# CORE_PRM register map
Vendor: Texas Instruments
Peripheral module from a debugger description file (folder omap5430_ES2_PUBLIC).
Registers are 32-bit, access not given, reset 0x1 unless marked. A register's access mark holds for its fields unless they carry their own. Offsets are as the file gives them; lines under a group give offsets from that group; [hi:lo] are bit positions; {n}, {i} and the like mark numbered series; 'fields as' and 'values as' point back to an identical list; <NAME> marks a mode.

## CORE_PRM
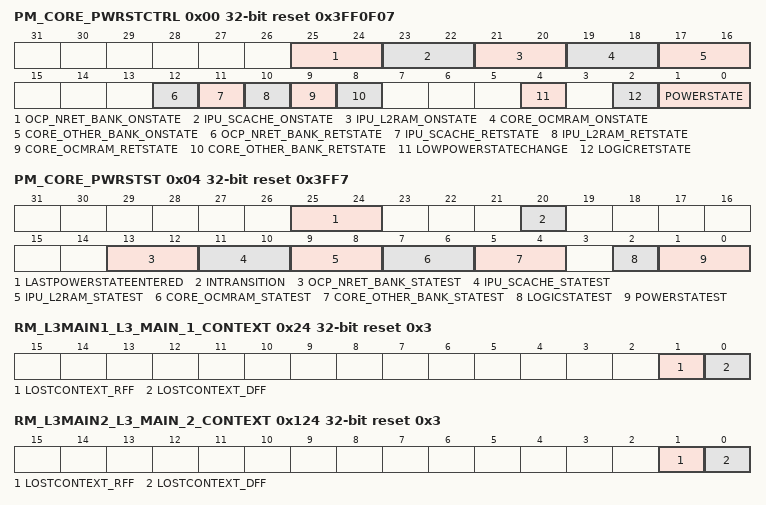
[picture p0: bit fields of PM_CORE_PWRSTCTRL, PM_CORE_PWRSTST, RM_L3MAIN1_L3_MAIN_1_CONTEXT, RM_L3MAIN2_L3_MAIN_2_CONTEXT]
0x00 PM_CORE_PWRSTCTRL reset 0x3FF0F07 — This register controls the CORE power state to reach upon a domain sleep transition
  [25:24] OCP_NRET_BANK_ONSTATE ro — OCP_NRET_BANK state when domain is ON.
    3=Mem_on (Memory bank is on when the domain is ON.)
  [23:22] IPU_SCACHE_ONSTATE ro — IPU SCACHE bank state when domain is ON.
    3=ON._3 (Memory bank is on when the domain is ON.)
  [21:20] IPU_L2RAM_ONSTATE ro — IPU L2 bank state when domain is ON.
    3=Mem_on (Memory bank is on when the domain is ON.)
  [19:18] CORE_OCMRAM_ONSTATE ro — OCMRAM bank state when domain is ON.
    3=Mem_on (Memory bank is on when the domain is ON.)
  [17:16] CORE_OTHER_BANK_ONSTATE ro — CORE_OTHER_BANK state when domain is ON.
    3=Mem_on (Memory bank is on when the domain is ON.)
  [12] OCP_NRET_BANK_RETSTATE ro — OCP_NRET_BANK state when domain is RETENTION.
    0=mem_off (Memory bank is off when the domain is in the RETENTION state.)
  [11] IPU_SCACHE_RETSTATE rw — IPU SCACHE bank state when domain is RETENTION.
    0=RETENTION_0 (Memory bank is off when the domain is in the RETENTION state.); 1=RETENTION_1 (Memory bank is retained when domain is in RETENTION state.)
  [10] IPU_L2RAM_RETSTATE rw — IPU L2 bank state when domain is RETENTION.
    0=mem_off (Memory bank is off when the domain is in the RETENTION state.); 1=mem_ret (Memory bank is retained when domain is in RETENTION state.)
  [9] CORE_OCMRAM_RETSTATE ro — OCMRAM bank state when domain is RETENTION.
    1=mem_ret (Memory bank is retained when domain is in RETENTION state.)
  [8] CORE_OTHER_BANK_RETSTATE ro — CORE_OTHER_BANK state when domain is RETENTION.
    values as CORE_OCMRAM_RETSTATE
  [4] LOWPOWERSTATECHANGE — Power state change request when domain has already performed a sleep transition. Allows going into deeper low power state without waking up the power domain. (access RW WSpecial)
    0=DIS (Do not request a low power state change.); 1=EN (Request a low power state change. This bit is automatically cleared when the power state is effectively changed or when power state is ON.)
  [2] LOGICRETSTATE rw — Logic state when power domain is RETENTION
    0=logic_off (Only retention registers are retained and remaing logic is off when the domain is in RETENTION state.); 1=logic_ret (Whole logic is retained when domain is in RETENTION state.)
  [1:0] POWERSTATE rw — Power state control
    1=RET (RETENTION state); 2=INACT (INACTIVE state); 3=ON (ON State)
0x04 PM_CORE_PWRSTST reset 0x3FF7 — This register provides a status on the current CORE power domain state. [warm reset insensitive]
  [25:24] LASTPOWERSTATEENTERED — Last low power state entered. Set to 0x3 upon write of the same only. This register is intended for debug purpose only. (access RW W1toSet)
    3=ON (Power domain was previously ON-ACTIVE); 2=INACTIVE (Power domain was previously ON-INACTIVE); 1=RET (Power domain was previously in RETENTION); 0=OFF (Reserved)
  [20] INTRANSITION ro — Domain transition status
    0=No (No on-going transition on power domain); 1=Ongoing (Power domain transition is in progress.)
  [13:12] OCP_NRET_BANK_STATEST ro — OCP_NRET_BANK bank state status
    0=Mem_off (Reserved); 3=Mem_on (Memory is ON)
  [11:10] IPU_SCACHE_STATEST ro — IPU SCACHE bank state status
    1=Memory_is_RETENTION; 3=Memory_is_ON
  [9:8] IPU_L2RAM_STATEST ro — IPU L2 bank state status
    0=Mem_off (Reserved); 1=Mem_ret (Memory is RETENTION); 3=Mem_on (Memory is ON)
  [7:6] CORE_OCMRAM_STATEST ro — OCMRAM bank state status
    values as IPU_L2RAM_STATEST
  [5:4] CORE_OTHER_BANK_STATEST ro — CORE_OTHER_BANK state status
    values as IPU_L2RAM_STATEST
  [2] LOGICSTATEST ro — Logic state status
    0=OFF (Logic in domain is OFF); 1=ON (Logic in domain is ON)
  [1:0] POWERSTATEST ro — Current power state status
    1=RET (Power domain is in RETENTION); 2=INACTIVE (Power domain is ON-INACTIVE); 3=ON (Power domain is ON-ACTIVE)
0x24 RM_L3MAIN1_L3_MAIN_1_CONTEXT reset 0x3 — This register contains dedicated L3_MAIN1 context statuses. [warm reset insensitive]
  [1] LOSTCONTEXT_RFF — Specify if RFF-based context has been lost due to a previous power transition or other reset source. (set upon assertion of CORE_PWRON_RET_RST signal) (access RW W1toClr)
    0=Maintained (Context has been maintained); 1=Lost (Context has been lost)
  [0] LOSTCONTEXT_DFF — Specify if DFF-based context has been lost due to a previous power transition or other reset source. (set upon assertion of CORE_RST signal) (access RW W1toClr)
    values as LOSTCONTEXT_RFF
0x124 RM_L3MAIN2_L3_MAIN_2_CONTEXT reset 0x3 — This register contains dedicated L3_MAIN2 context statuses. [warm reset insensitive]
  fields as RM_L3MAIN1_L3_MAIN_1_CONTEXT
0x12C RM_L3MAIN2_GPMC_CONTEXT reset 0x2 — This register contains dedicated GPMC context statuses. [warm reset insensitive]
  [1] LOSTCONTEXT_RFF — Specify if RFF-based context has been lost due to a previous power transition or other reset source. (set upon assertion of CORE_RET_RST signal) (access RW W1toClr)
    values as RM_L3MAIN1_L3_MAIN_1_CONTEXT.LOSTCONTEXT_RFF
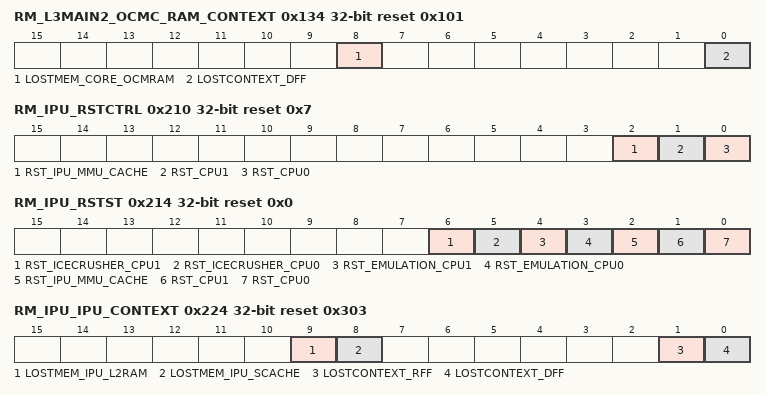
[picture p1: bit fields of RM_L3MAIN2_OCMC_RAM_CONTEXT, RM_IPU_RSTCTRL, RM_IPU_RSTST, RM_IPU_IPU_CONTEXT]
0x134 RM_L3MAIN2_OCMC_RAM_CONTEXT reset 0x101 — This register contains dedicated OCMC_RAM context statuses. [warm reset insensitive]
  [8] LOSTMEM_CORE_OCMRAM — Specify if memory-based context in CORE_OCMRAM memory bank has been lost due to a previous power transition or other reset source (not affected by a global warm reset). (access RW W1toClr)
    values as RM_L3MAIN1_L3_MAIN_1_CONTEXT.LOSTCONTEXT_RFF
  [0] LOSTCONTEXT_DFF — Specify if DFF-based context has been lost due to a previous power transition or other reset source. (set upon assertion of CORE_RST signal) (access RW W1toClr)
    values as RM_L3MAIN1_L3_MAIN_1_CONTEXT.LOSTCONTEXT_RFF
0x210 RM_IPU_RSTCTRL access per field reset 0x7 — This register controls the release of the IPU sub-system resets.
  [2] RST_IPU_MMU_CACHE rw — IPU MMU and CACHE interface reset control.
    0=CLEAR (Reset is cleared for IPU CACHE and MMU); 1=ASSERT (Reset is asserted for the IPU CACHE and MMU)
  [1] RST_CPU1 rw — IPU CPU1 reset control.
    0=CLEAR (Reset is cleared for the IPU CPU1); 1=ASSERT (Reset is asserted for the IPU CPU1)
  [0] RST_CPU0 rw — IPU CPU0 reset control.
    0=CLEAR (Reset is cleared for the IPU CPU0); 1=ASSERT (Reset is asserted for the IPU CPU0)
0x214 RM_IPU_RSTST reset 0x0 — This register logs the different reset sources of the IPU SS. Each bit is set upon release of the domain reset signal. Must be cleared by software. [warm reset insensitive]
  [6] RST_ICECRUSHER_CPU1 — IPU CPU1 has been reset due to IPU ICECRUSHER1 reset source (access RW W1toClr)
    0=RESET_NO (No icecrusher reset); 1=RESET_YES (IPU CPU1 has been reset upon icecrusher reset)
  [5] RST_ICECRUSHER_CPU0 — IPU CPU0 has been reset due to IPU ICECRUSHER0 reset source (access RW W1toClr)
    0=RESET_NO (No icecrusher reset); 1=RESET_YES (CPU0 has been reset upon icecrusher reset)
  [4] RST_EMULATION_CPU1 — IPU CPU1 has been reset due to emulation reset source e.g. assert reset command initiated by the icepick module (access RW W1toClr)
    0=RESET_NO (No emulation reset); 1=RESET_YES (IPU CPU1 has been reset upon emulation reset)
  [3] RST_EMULATION_CPU0 — IPU CPU0 has been reset due to emulation reset source e.g. assert reset command initiated by the icepick module (access RW W1toClr)
    0=RESET_NO (No emulation reset); 1=RESET_YES (IPU CPU0 has been reset upon emulation reset)
  [2] RST_IPU_MMU_CACHE — IPU MMU and CACHE interface SW reset status (access RW W1toClr)
    0=RESET_NO (No SW reset occured); 1=RESET_YES (IPU MMU and CACHE interface has been reset upon SW reset)
  [1] RST_CPU1 — IPU CPU1 SW reset status (access RW W1toClr)
    0=RESET_NO (No SW reset occured); 1=RESET_YES (IPU CPU1 has been reset upon SW reset)
  [0] RST_CPU0 — IPU CPU0 SW reset status (access RW W1toClr)
    0=RESET_NO (No SW reset occured); 1=RESET_YES (IPU CPU0 has been reset upon SW reset)
0x224 RM_IPU_IPU_CONTEXT reset 0x303 — This register contains dedicated IPU context statuses. [warm reset insensitive]
  [9] LOSTMEM_IPU_L2RAM — Specify if memory-based context in IPU_L2RAM memory bank has been lost due to a previous power transition or other reset source. (access RW W1toClr)
    values as RM_L3MAIN1_L3_MAIN_1_CONTEXT.LOSTCONTEXT_RFF
  [8] LOSTMEM_IPU_SCACHE — Specify if memory-based context in IPU_SCACHE memory bank has been lost due to a previous power transition or other reset source. (access RW W1toClr)
    0=Context_has_been_maintained; 1=Context_has_been_lost
  [1] LOSTCONTEXT_RFF — Specify if RFF-based context has been lost due to a previous power transition or other reset source. (set upon assertion of IPU_RET_RST signal) (access RW W1toClr)
    values as RM_L3MAIN1_L3_MAIN_1_CONTEXT.LOSTCONTEXT_RFF
  [0] LOSTCONTEXT_DFF — Specify if DFF-based context has been lost due to a previous power transition or other reset source. (set upon assertion of IPU_RST3 signal) (access RW W1toClr)
    values as RM_L3MAIN1_L3_MAIN_1_CONTEXT.LOSTCONTEXT_RFF
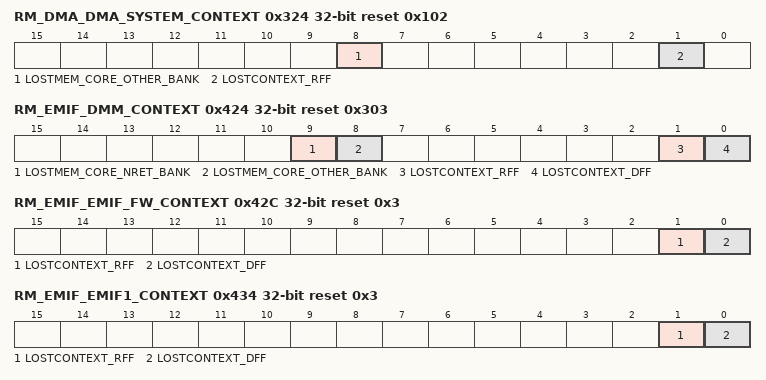
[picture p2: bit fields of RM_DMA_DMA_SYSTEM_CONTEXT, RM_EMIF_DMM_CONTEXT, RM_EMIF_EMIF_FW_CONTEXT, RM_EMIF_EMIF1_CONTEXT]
0x324 RM_DMA_DMA_SYSTEM_CONTEXT reset 0x102 — This register contains dedicated DMA_SYSTEM context statuses. [warm reset insensitive]
  [8] LOSTMEM_CORE_OTHER_BANK — Specify if memory-based context in CORE_OTHER_BANK memory bank has been lost due to a previous power transition or other reset source. (access RW W1toClr)
    values as RM_L3MAIN1_L3_MAIN_1_CONTEXT.LOSTCONTEXT_RFF
  [1] LOSTCONTEXT_RFF — Specify if RFF-based context has been lost due to a previous power transition or other reset source. (set upon assertion of SDMA_RET_RST signal) (access RW W1toClr)
    values as RM_L3MAIN1_L3_MAIN_1_CONTEXT.LOSTCONTEXT_RFF
0x424 RM_EMIF_DMM_CONTEXT reset 0x303 — This register contains dedicated DMM context statuses. [warm reset insensitive]
  [all] fields
    values as RM_L3MAIN1_L3_MAIN_1_CONTEXT.LOSTCONTEXT_RFF
  [9] LOSTMEM_CORE_NRET_BANK — Specify if memory-based context in CORE_NRET_BANK memory bank has been lost due to a previous power transition or other reset source. (access RW W1toClr)
  [8] LOSTMEM_CORE_OTHER_BANK — Specify if memory-based context in CORE_OTHER_BANK memory bank has been lost due to a previous power transition or other reset source. (access RW W1toClr)
  [1] LOSTCONTEXT_RFF — Specify if RFF-based context has been lost due to a previous power transition or other reset source. (set upon assertion of CORE_RET_RST signal) (access RW W1toClr)
  [0] LOSTCONTEXT_DFF — Specify if DFF-based context has been lost due to a previous power transition or other reset source. (set upon assertion of CORE_RST signal) (access RW W1toClr)
0x42C RM_EMIF_EMIF_FW_CONTEXT reset 0x3 — This register contains dedicated EMIF_FW context statuses. [warm reset insensitive]
  [1] LOSTCONTEXT_RFF — Specify if RFF-based context has been lost due to a previous power transition or other reset source. (set upon assertion of CORE_PWRON_RET_RST signal) (access RW W1toClr)
    0=Context_has_been_maintained; 1=Context_has_been_lost
  [0] LOSTCONTEXT_DFF — Specify if DFF-based context has been lost due to a previous power transition or other reset source. (set upon assertion of CORE_RST signal) (access RW W1toClr)
    0=Context_has_been_maintained; 1=Context_has_been_lost
0x434 RM_EMIF_EMIF1_CONTEXT reset 0x3 — This register contains dedicated EMIF1 context statuses. [warm reset insensitive]
  [1] LOSTCONTEXT_RFF — Specify if RFF-based context has been lost due to a previous power transition or other reset source. (set upon assertion of CORE_PWRON_RET_RST signal) (access RW W1toClr)
    values as RM_L3MAIN1_L3_MAIN_1_CONTEXT.LOSTCONTEXT_RFF
  [0] LOSTCONTEXT_DFF — Specify if DFF-based context has been lost due to a previous power transition or other reset source. (set upon assertion of CORE_PWRON_RST signal) (access RW W1toClr)
    values as RM_L3MAIN1_L3_MAIN_1_CONTEXT.LOSTCONTEXT_RFF
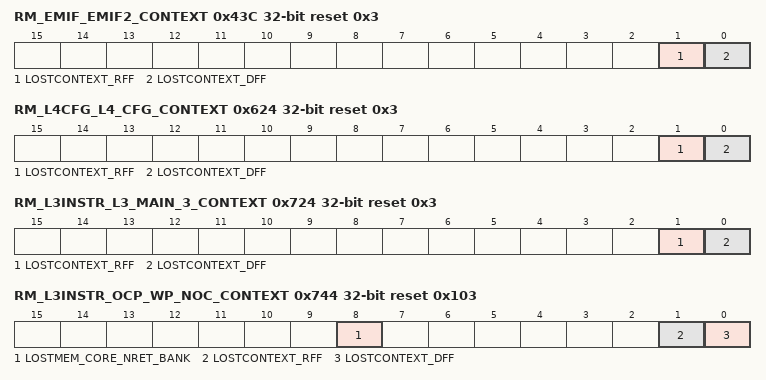
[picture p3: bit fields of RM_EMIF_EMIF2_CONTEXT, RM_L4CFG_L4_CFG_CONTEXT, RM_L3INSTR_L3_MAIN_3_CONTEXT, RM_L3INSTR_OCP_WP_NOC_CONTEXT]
0x43C RM_EMIF_EMIF2_CONTEXT reset 0x3 — This register contains dedicated EMIF2 context statuses. [warm reset insensitive]
  fields as RM_EMIF_EMIF1_CONTEXT
0x444 RM_EMIF_EMIF_DLL_CONTEXT — This register contains dedicated DLL context statuses. [warm reset insensitive]
  [0] LOSTCONTEXT_DFF — Specify if DFF-based context has been lost due to a previous power transition or other reset source. (set upon assertion of DLL_RST signal) (access RW W1toClr)
    values as RM_L3MAIN1_L3_MAIN_1_CONTEXT.LOSTCONTEXT_RFF
0x624 RM_L4CFG_L4_CFG_CONTEXT reset 0x3 — This register contains dedicated L4_CFG context statuses. [warm reset insensitive]
  fields as RM_L3MAIN1_L3_MAIN_1_CONTEXT
0x62C RM_L4CFG_SPINLOCK_CONTEXT reset 0x2 — This register contains dedicated HW_SEM context statuses. [warm reset insensitive]
  fields as RM_L3MAIN2_GPMC_CONTEXT
0x634 RM_L4CFG_MAILBOX_CONTEXT reset 0x2 — This register contains dedicated MAILBOX context statuses. [warm reset insensitive]
  fields as RM_L3MAIN2_GPMC_CONTEXT
0x63C RM_L4CFG_SAR_ROM_CONTEXT — This register contains dedicated SAR_ROM context statuses. [warm reset insensitive]
  [0] LOSTCONTEXT_DFF — Specify if DFF-based context has been lost due to a previous power transition or other reset source. (set upon assertion of CORE_RST signal) (access RW W1toClr)
    values as RM_L3MAIN1_L3_MAIN_1_CONTEXT.LOSTCONTEXT_RFF
0x724 RM_L3INSTR_L3_MAIN_3_CONTEXT reset 0x3 — This register contains dedicated L3_MAIN3 context statuses. [warm reset insensitive]
  fields as RM_L3MAIN1_L3_MAIN_1_CONTEXT
0x72C RM_L3INSTR_L3_INSTR_CONTEXT — This register contains dedicated L3_INSTR context statuses. [warm reset insensitive]
  fields as RM_L4CFG_SAR_ROM_CONTEXT
0x744 RM_L3INSTR_OCP_WP_NOC_CONTEXT reset 0x103 — This register contains dedicated OCP_WP_NOC context statuses. [warm reset insensitive]
  [all] fields
    values as RM_L3MAIN1_L3_MAIN_1_CONTEXT.LOSTCONTEXT_RFF
  [8] LOSTMEM_CORE_NRET_BANK — Specify if memory-based context in CORE_NRET_BANK memory bank has been lost due to a previous power transition or other reset source. (access RW W1toClr)
  [1] LOSTCONTEXT_RFF — Specify if RFF-based context has been lost due to a previous power transition or other reset source. (set upon assertion of CORE_PWRON_RET_RST signal) (access RW W1toClr)
  [0] LOSTCONTEXT_DFF — Specify if DFF-based context has been lost due to a previous power transition or other reset source. (set upon assertion of CORE_RST signal) (access RW W1toClr)
0x928 PM_L4PER_TIMER10_WKDEP access per field — This register controls wakeup dependency based on TIMER10 service requests.
  [0] WKUPDEP_TIMER10_MPU rw — Wakeup dependency from TIMER10 module (SWakeup signal) towards MPU + L3MAIN1 + L3MAIN2 domains
    0=Disabled (Dependency is disabled); 1=Enabled (Dependency is enabled)
0x92C RM_L4PER_TIMER10_CONTEXT — This register contains dedicated TIMER10 context statuses. [warm reset insensitive]
  fields as RM_L4CFG_SAR_ROM_CONTEXT
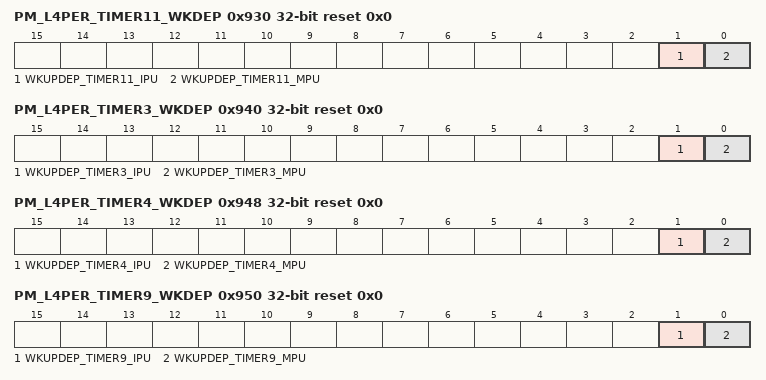
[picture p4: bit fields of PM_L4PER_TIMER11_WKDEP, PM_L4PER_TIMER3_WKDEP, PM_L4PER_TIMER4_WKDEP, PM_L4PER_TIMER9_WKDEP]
0x930 PM_L4PER_TIMER11_WKDEP access per field reset 0x0 — This register controls wakeup dependency based on TIMER11 service requests.
  [1] WKUPDEP_TIMER11_IPU rw — Wakeup dependency from TIMER11 module (SWakeup signal) towards IPU + L3MAIN2 domains
    values as PM_L4PER_TIMER10_WKDEP.WKUPDEP_TIMER10_MPU
  [0] WKUPDEP_TIMER11_MPU rw — Wakeup dependency from TIMER11 module (SWakeup signal) towards MPU + L3MAIN1 + L3MAIN2 domains
    values as PM_L4PER_TIMER10_WKDEP.WKUPDEP_TIMER10_MPU
0x934 RM_L4PER_TIMER11_CONTEXT — This register contains dedicated TIMER11 context statuses. [warm reset insensitive]
  fields as RM_L4CFG_SAR_ROM_CONTEXT
0x938 PM_L4PER_TIMER2_WKDEP access per field — This register controls wakeup dependency based on TIMER2 service requests.
  [0] WKUPDEP_TIMER2_MPU rw — Wakeup dependency from TIMER2 module (SWakeup signal) towards MPU + L3MAIN1 + L3MAIN2 domains
    values as PM_L4PER_TIMER10_WKDEP.WKUPDEP_TIMER10_MPU
{0x92C+8i} RM_L4PER_TIMER{i}_CONTEXT (i=2..4) — This register contains dedicated TIMER{i} context statuses. [warm reset insensitive]
  fields as RM_L4CFG_SAR_ROM_CONTEXT
0x940 PM_L4PER_TIMER3_WKDEP access per field reset 0x0 — This register controls wakeup dependency based on TIMER3 service requests.
  [1] WKUPDEP_TIMER3_IPU rw — Wakeup dependency from TIMER3 module (SWakeup signal) towards IPU + L3MAIN2 domains
    values as PM_L4PER_TIMER10_WKDEP.WKUPDEP_TIMER10_MPU
  [0] WKUPDEP_TIMER3_MPU rw — Wakeup dependency from TIMER3 module (SWakeup signal) towards MPU + L3MAIN1 + L3MAIN2 domains
    values as PM_L4PER_TIMER10_WKDEP.WKUPDEP_TIMER10_MPU
0x948 PM_L4PER_TIMER4_WKDEP access per field reset 0x0 — This register controls wakeup dependency based on TIMER4 service requests.
  [1] WKUPDEP_TIMER4_IPU rw — Wakeup dependency from TIMER4 module (SWakeup signal) towards IPU + L3MAIN2 domains
    values as PM_L4PER_TIMER10_WKDEP.WKUPDEP_TIMER10_MPU
  [0] WKUPDEP_TIMER4_MPU rw — Wakeup dependency from TIMER4 module (SWakeup signal) towards MPU + L3MAIN1 + L3MAIN2 domains
    values as PM_L4PER_TIMER10_WKDEP.WKUPDEP_TIMER10_MPU
0x950 PM_L4PER_TIMER9_WKDEP access per field reset 0x0 — This register controls wakeup dependency based on TIMER9 service requests.
  [1] WKUPDEP_TIMER9_IPU rw — Wakeup dependency from TIMER9 module (SWakeup signal) towards IPU + L3MAIN2 domains
    values as PM_L4PER_TIMER10_WKDEP.WKUPDEP_TIMER10_MPU
  [0] WKUPDEP_TIMER9_MPU rw — Wakeup dependency from TIMER9 module (SWakeup signal) towards MPU + L3MAIN1 + L3MAIN2 domains
    values as PM_L4PER_TIMER10_WKDEP.WKUPDEP_TIMER10_MPU
0x954 RM_L4PER_TIMER9_CONTEXT — This register contains dedicated TIMER9 context statuses. [warm reset insensitive]
  fields as RM_L4CFG_SAR_ROM_CONTEXT
0x95C RM_L4PER_ELM_CONTEXT — This register contains dedicated ELM context statuses. [warm reset insensitive]
  fields as RM_L4CFG_SAR_ROM_CONTEXT
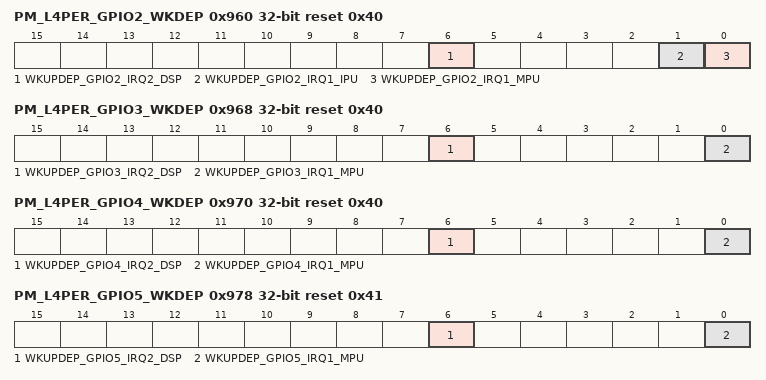
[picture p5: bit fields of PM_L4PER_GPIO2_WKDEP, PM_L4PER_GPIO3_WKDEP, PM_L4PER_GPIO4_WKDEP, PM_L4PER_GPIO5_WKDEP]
0x960 PM_L4PER_GPIO2_WKDEP access per field reset 0x40 — This register controls wakeup dependency based on GPIO2 service requests.
  [all] fields
    values as PM_L4PER_TIMER10_WKDEP.WKUPDEP_TIMER10_MPU
  [6] WKUPDEP_GPIO2_IRQ2_DSP rw — Wakeup dependency from GPIO2 module (POINTRSWAKEUP2 signal) towards DSP + L3MAIN1 + L3MAIN2 domains
  [1] WKUPDEP_GPIO2_IRQ1_IPU rw — Wakeup dependency from GPIO2 module (POINTRSWAKEUP1 signal) module towards IPU + L3MAIN2 domains
  [0] WKUPDEP_GPIO2_IRQ1_MPU rw — Wakeup dependency from GPIO2 module (POINTRSWAKEUP1 signal) towards MPU + L3MAIN1 + L3MAIN2 domains
{0x954+8i} RM_L4PER_GPIO{i}_CONTEXT reset 0x2 (i=2..6) — This register contains dedicated GPIO{i} context statuses. [warm reset insensitive]
  fields as RM_L3MAIN2_GPMC_CONTEXT
0x968 PM_L4PER_GPIO3_WKDEP access per field reset 0x40 — This register controls wakeup dependency based on GPIO3 service requests.
  [6] WKUPDEP_GPIO3_IRQ2_DSP rw — Wakeup dependency from GPIO3 module (POINTRSWAKEUP2 signal) towards DSP + L3MAIN1 + L3MAIN2 domains
    values as PM_L4PER_TIMER10_WKDEP.WKUPDEP_TIMER10_MPU
  [0] WKUPDEP_GPIO3_IRQ1_MPU rw — Wakeup dependency from GPIO3 module (POINTRSWAKEUP1 signal) towards MPU + L3MAIN1 + L3MAIN2 domains
    values as PM_L4PER_TIMER10_WKDEP.WKUPDEP_TIMER10_MPU
0x970 PM_L4PER_GPIO4_WKDEP access per field reset 0x40 — This register controls wakeup dependency based on GPIO4 service requests.
  [6] WKUPDEP_GPIO4_IRQ2_DSP rw — Wakeup dependency from GPIO4 module (POINTRSWAKEUP2 signal) towards DSP + L3MAIN1 + L3MAIN2 domains
    values as PM_L4PER_TIMER10_WKDEP.WKUPDEP_TIMER10_MPU
  [0] WKUPDEP_GPIO4_IRQ1_MPU rw — Wakeup dependency from GPIO4 module (POINTRSWAKEUP1 signal) towards MPU + L3MAIN1 + L3MAIN2 domains
    values as PM_L4PER_TIMER10_WKDEP.WKUPDEP_TIMER10_MPU
0x978 PM_L4PER_GPIO5_WKDEP access per field reset 0x41 — This register controls wakeup dependency based on GPIO5 service requests.
  [6] WKUPDEP_GPIO5_IRQ2_DSP rw — Wakeup dependency from GPIO5 module (POINTRSWAKEUP2 signal) towards DSP + L3MAIN1 + L3MAIN2 domains
    values as PM_L4PER_TIMER10_WKDEP.WKUPDEP_TIMER10_MPU
  [0] WKUPDEP_GPIO5_IRQ1_MPU rw — Wakeup dependency from GPIO5 module (POINTRSWAKEUP1 signal) towards MPU + L3MAIN1 + L3MAIN2 domains
    values as PM_L4PER_TIMER10_WKDEP.WKUPDEP_TIMER10_MPU
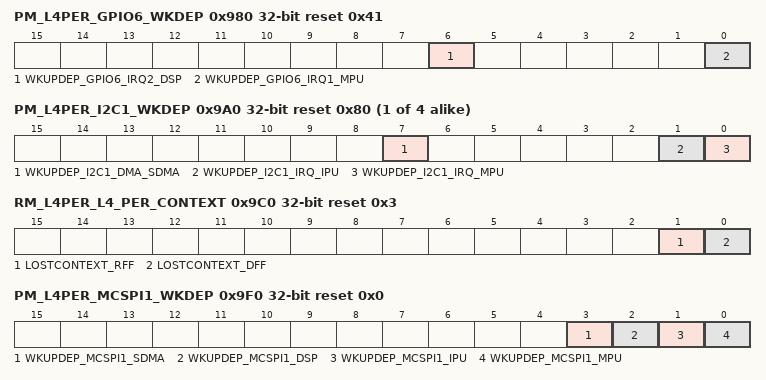
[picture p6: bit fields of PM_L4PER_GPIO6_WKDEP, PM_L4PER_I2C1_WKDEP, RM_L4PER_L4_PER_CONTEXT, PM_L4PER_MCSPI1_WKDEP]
0x980 PM_L4PER_GPIO6_WKDEP access per field reset 0x41 — This register controls wakeup dependency based on GPIO6 service requests.
  [6] WKUPDEP_GPIO6_IRQ2_DSP rw — Wakeup dependency from GPIO6 module (POINTRSWAKEUP2 signal) towards DSP + L3MAIN1 + L3MAIN2 domains
    values as PM_L4PER_TIMER10_WKDEP.WKUPDEP_TIMER10_MPU
  [0] WKUPDEP_GPIO6_IRQ1_MPU rw — Wakeup dependency from GPIO6 module (POINTRSWAKEUP1 signal) towards MPU + L3MAIN1 + L3MAIN2 domains
    values as PM_L4PER_TIMER10_WKDEP.WKUPDEP_TIMER10_MPU
0x98C RM_L4PER_HDQ1W_CONTEXT — This register contains dedicated HDQ1W context statuses. [warm reset insensitive]
  fields as RM_L4CFG_SAR_ROM_CONTEXT
{0x998+8i} PM_L4PER_I2C{i}_WKDEP access per field reset 0x80 (i=1..4) — This register controls wakeup dependency based on I2C{i} service requests.
  [all] fields
    values as PM_L4PER_TIMER10_WKDEP.WKUPDEP_TIMER10_MPU
  [7] WKUPDEP_I2C{i}_DMA_SDMA rw — Wakeup dependency from I2C{i} module (SWakeup_dma signal) towards SDMA + L3MAIN2 domains
  [1] WKUPDEP_I2C{i}_IRQ_IPU rw — Wakeup dependency from I2C{i} module (SWakeup_irq signal) towards IPU + L3MAIN2 domains
  [0] WKUPDEP_I2C{i}_IRQ_MPU rw — Wakeup dependency from I2C{i} module (SWakeup_irq signal) towards MPU + L3MAIN1 + L3MAIN2 domains
0x9A4 RM_L4PER_I2C1_CONTEXT reset 0x2 — This register contains dedicated I2C1 context statuses. [warm reset insensitive]
  fields as RM_L3MAIN2_GPMC_CONTEXT
{0x99C+8i} RM_L4PER_I2C{i}_CONTEXT (i=2..4) — This register contains dedicated I2C{i} context statuses. [warm reset insensitive]
  fields as RM_L4CFG_SAR_ROM_CONTEXT
0x9C0 RM_L4PER_L4_PER_CONTEXT reset 0x3 — This register contains dedicated L4_PER context statuses. [warm reset insensitive]
  fields as RM_L3MAIN1_L3_MAIN_1_CONTEXT
0x9F0 PM_L4PER_MCSPI1_WKDEP access per field reset 0x0 — This register controls wakeup dependency based on MCSPI1 service requests.
  [all] fields
    values as PM_L4PER_TIMER10_WKDEP.WKUPDEP_TIMER10_MPU
  [3] WKUPDEP_MCSPI1_SDMA rw — Wakeup dependency from MCSPI1 module (SWakeup signal) towards SDMA + L3MAIN2 domains
  [2] WKUPDEP_MCSPI1_DSP rw — Wakeup dependency from MCSPI1 module (SWakeup signal) towards DSP + L3MAIN1 + L3MAIN2 domains
  [1] WKUPDEP_MCSPI1_IPU rw — Wakeup dependency from MCSPI1 module (SWakeup signal) towards IPU + L3MAIN2 domains
  [0] WKUPDEP_MCSPI1_MPU rw — Wakeup dependency from MCSPI1 module (SWakeup signal) towards MPU + L3MAIN1 + L3MAIN2 domains
{0x9EC+8i} RM_L4PER_MCSPI{i}_CONTEXT (i=1..4) — This register contains dedicated MCSPI{i} context statuses. [warm reset insensitive]
  fields as RM_L4CFG_SAR_ROM_CONTEXT
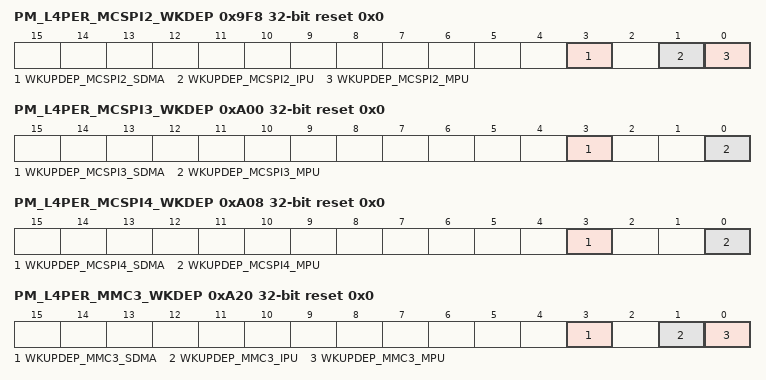
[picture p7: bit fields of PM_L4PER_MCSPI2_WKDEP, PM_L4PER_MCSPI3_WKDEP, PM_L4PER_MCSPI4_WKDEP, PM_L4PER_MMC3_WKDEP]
0x9F8 PM_L4PER_MCSPI2_WKDEP access per field reset 0x0 — This register controls wakeup dependency based on MCSPI2 service requests.
  [all] fields
    values as PM_L4PER_TIMER10_WKDEP.WKUPDEP_TIMER10_MPU
  [3] WKUPDEP_MCSPI2_SDMA rw — Wakeup dependency from MCSPI2 module (SWakeup signal) towards SDMA + L3MAIN2 domains
  [1] WKUPDEP_MCSPI2_IPU rw — Wakeup dependency from MCSPI2 module (SWakeup signal) towards IPU + L3MAIN2 domains
  [0] WKUPDEP_MCSPI2_MPU rw — Wakeup dependency from MCSPI2 module (SWakeup signal) towards MPU + L3MAIN1 + L3MAIN2 domains
0xA00 PM_L4PER_MCSPI3_WKDEP access per field reset 0x0 — This register controls wakeup dependency based on MCSPI3 service requests.
  [3] WKUPDEP_MCSPI3_SDMA rw — Wakeup dependency from MCSPI3 module (SWakeup signal) towards SDMA + L3MAIN2 domains
    values as PM_L4PER_TIMER10_WKDEP.WKUPDEP_TIMER10_MPU
  [0] WKUPDEP_MCSPI3_MPU rw — Wakeup dependency from MCSPI3 module (SWakeup signal) towards MPU + L3MAIN1 + L3MAIN2 domains
    values as PM_L4PER_TIMER10_WKDEP.WKUPDEP_TIMER10_MPU
0xA08 PM_L4PER_MCSPI4_WKDEP access per field reset 0x0 — This register controls wakeup dependency based on MCSPI4 service requests.
  [3] WKUPDEP_MCSPI4_SDMA rw — Wakeup dependency from MCSPI4 module (SWakeup signal) towards SDMA + L3MAIN2 domains
    values as PM_L4PER_TIMER10_WKDEP.WKUPDEP_TIMER10_MPU
  [0] WKUPDEP_MCSPI4_MPU rw — Wakeup dependency from MCSPI4 module (SWakeup signal) towards MPU + L3MAIN1 + L3MAIN2 domains
    values as PM_L4PER_TIMER10_WKDEP.WKUPDEP_TIMER10_MPU
0xA10 PM_L4PER_GPIO7_WKDEP access per field — This register controls wakeup dependency based on GPIO7 service requests.
  [0] WKUPDEP_GPIO7_IRQ1_MPU rw — Wakeup dependency from GPIO7 module (POINTRSWAKEUP1 signal) towards MPU + L3MAIN1 + L3MAIN2 domains
    values as PM_L4PER_TIMER10_WKDEP.WKUPDEP_TIMER10_MPU
0xA14 RM_L4PER_GPIO7_CONTEXT reset 0x2 — This register contains dedicated GPIO7 context statuses. [warm reset insensitive]
  fields as RM_L3MAIN2_GPMC_CONTEXT
0xA18 PM_L4PER_GPIO8_WKDEP access per field — This register controls wakeup dependency based on GPIO8 service requests.
  [0] WKUPDEP_GPIO8_IRQ1_MPU rw — Wakeup dependency from GPIO8 module (POINTRSWAKEUP1 signal) towards MPU + L3MAIN1 + L3MAIN2 domains
    values as PM_L4PER_TIMER10_WKDEP.WKUPDEP_TIMER10_MPU
0xA1C RM_L4PER_GPIO8_CONTEXT reset 0x2 — This register contains dedicated GPIO8 context statuses. [warm reset insensitive]
  fields as RM_L3MAIN2_GPMC_CONTEXT
0xA20 PM_L4PER_MMC3_WKDEP access per field reset 0x0 — This register controls wakeup dependency based on MMC3 service requests.
  [all] fields
    values as PM_L4PER_TIMER10_WKDEP.WKUPDEP_TIMER10_MPU
  [3] WKUPDEP_MMC3_SDMA rw — Wakeup dependency from MMCSD3 module (SWakeup signal) towards SDMA + L3MAIN2 domains
  [1] WKUPDEP_MMC3_IPU rw — Wakeup dependency from MMCSD3 module (SWakeup signal) towards IPU + L3MAIN2 domains
  [0] WKUPDEP_MMC3_MPU rw — Wakeup dependency from MMCSD3 module (SWakeup signal) towards MPU + L3MAIN1 + L3MAIN2 domains
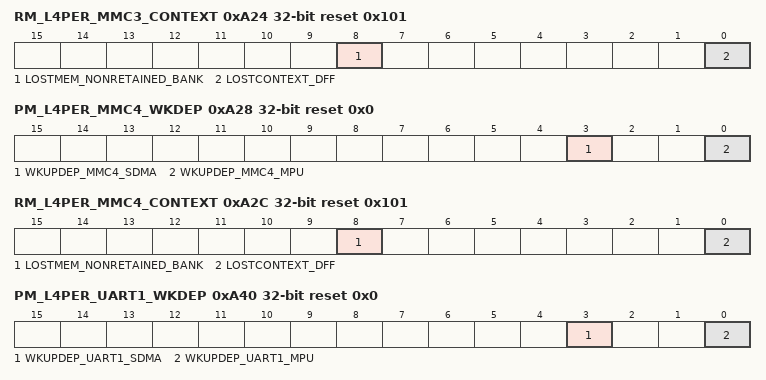
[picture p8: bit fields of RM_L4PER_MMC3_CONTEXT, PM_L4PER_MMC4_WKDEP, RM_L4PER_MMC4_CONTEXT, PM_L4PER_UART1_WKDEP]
0xA24 RM_L4PER_MMC3_CONTEXT reset 0x101 — This register contains dedicated MMC3 context statuses. [warm reset insensitive]
  [8] LOSTMEM_NONRETAINED_BANK — Specify if memory-based context in NONRETAINED_BANK memory bank has been lost due to a previous power transition or other reset source. (access RW W1toClr)
    values as RM_L3MAIN1_L3_MAIN_1_CONTEXT.LOSTCONTEXT_RFF
  [0] LOSTCONTEXT_DFF — Specify if DFF-based context has been lost due to a previous power transition or other reset source. (set upon assertion of CORE_RST signal) (access RW W1toClr)
    values as RM_L3MAIN1_L3_MAIN_1_CONTEXT.LOSTCONTEXT_RFF
0xA28 PM_L4PER_MMC4_WKDEP access per field reset 0x0 — This register controls wakeup dependency based on MMC4 service requests.
  [3] WKUPDEP_MMC4_SDMA rw — Wakeup dependency from MMCSD4 module (SWakeup signal) towards SDMA + L3MAIN2 domains
    values as PM_L4PER_TIMER10_WKDEP.WKUPDEP_TIMER10_MPU
  [0] WKUPDEP_MMC4_MPU rw — Wakeup dependency from MMCSD4 module (SWakeup signal) towards MPU + L3MAIN1 + L3MAIN2 domains
    values as PM_L4PER_TIMER10_WKDEP.WKUPDEP_TIMER10_MPU
0xA2C RM_L4PER_MMC4_CONTEXT reset 0x101 — This register contains dedicated MMC4 context statuses. [warm reset insensitive]
  fields as RM_L4PER_MMC3_CONTEXT
0xA40 PM_L4PER_UART1_WKDEP access per field reset 0x0 — This register controls wakeup dependency based on UART1 service requests.
  [3] WKUPDEP_UART1_SDMA rw — Wakeup dependency from UART1 module (SWakeup signal) towards SDMA + L3MAIN2 domains
    values as PM_L4PER_TIMER10_WKDEP.WKUPDEP_TIMER10_MPU
  [0] WKUPDEP_UART1_MPU rw — Wakeup dependency from UART1 module (SWakeup signal) towards MPU + L3MAIN1 + L3MAIN2 domains
    values as PM_L4PER_TIMER10_WKDEP.WKUPDEP_TIMER10_MPU
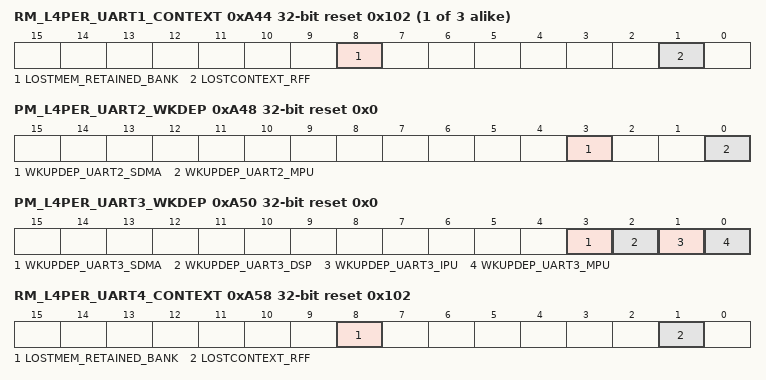
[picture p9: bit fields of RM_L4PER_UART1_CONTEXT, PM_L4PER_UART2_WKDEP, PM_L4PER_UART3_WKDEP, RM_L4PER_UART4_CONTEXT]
{0xA3C+8i} RM_L4PER_UART{i}_CONTEXT reset 0x102 (i=1..3) — This register contains dedicated UART{i} context statuses. [warm reset insensitive]
  [8] LOSTMEM_RETAINED_BANK — Specify if memory-based context in RETAINED_BANK memory bank has been lost due to a previous power transition or other reset source. (access RW W1toClr)
    values as RM_L3MAIN1_L3_MAIN_1_CONTEXT.LOSTCONTEXT_RFF
  [1] LOSTCONTEXT_RFF — Specify if RFF-based context has been lost due to a previous power transition or other reset source. (set upon assertion of CORE_RET_RST signal) (access RW W1toClr)
    values as RM_L3MAIN1_L3_MAIN_1_CONTEXT.LOSTCONTEXT_RFF
0xA48 PM_L4PER_UART2_WKDEP access per field reset 0x0 — This register controls wakeup dependency based on UART2 service requests.
  [3] WKUPDEP_UART2_SDMA rw — Wakeup dependency from UART2 module (SWakeup signal) towards SDMA + L3MAIN2 domains
    values as PM_L4PER_TIMER10_WKDEP.WKUPDEP_TIMER10_MPU
  [0] WKUPDEP_UART2_MPU rw — Wakeup dependency from UART2 module (SWakeup signal) towards MPU + L3MAIN1 + L3MAIN2 domains
    values as PM_L4PER_TIMER10_WKDEP.WKUPDEP_TIMER10_MPU
0xA50 PM_L4PER_UART3_WKDEP access per field reset 0x0 — This register controls wakeup dependency based on UART3 service requests.
  [all] fields
    values as PM_L4PER_TIMER10_WKDEP.WKUPDEP_TIMER10_MPU
  [3] WKUPDEP_UART3_SDMA rw — Wakeup dependency from UART3 module (SWakeup signal) towards SDMA + L3MAIN2 domains
  [2] WKUPDEP_UART3_DSP rw — Wakeup dependency from UART3 module (SWakeup signal) towards DSP + L3MAIN1 + L3MAIN2 domains
  [1] WKUPDEP_UART3_IPU rw — Wakeup dependency from UART3 module (SWakeup signal) towards IPU + L3MAIN2 domains
  [0] WKUPDEP_UART3_MPU rw — Wakeup dependency from UART3 module (SWakeup signal) towards MPU + L3MAIN1 + L3MAIN2 domains
0xA58 RM_L4PER_UART4_CONTEXT reset 0x102 — This register contains dedicated UART4 context statuses. [warm reset insensitive]
  fields as RM_L4PER_UART1_CONTEXT
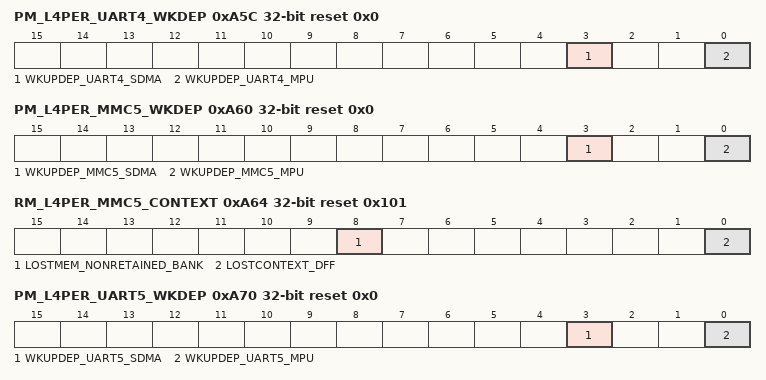
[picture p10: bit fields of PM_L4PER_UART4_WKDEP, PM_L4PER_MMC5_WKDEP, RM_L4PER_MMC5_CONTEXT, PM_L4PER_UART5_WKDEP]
0xA5C PM_L4PER_UART4_WKDEP access per field reset 0x0 — This register controls wakeup dependency based on UART4 service requests.
  [3] WKUPDEP_UART4_SDMA rw — Wakeup dependency from UART4 module (SWakeup signal) towards SDMA + L3MAIN2 domains
    values as PM_L4PER_TIMER10_WKDEP.WKUPDEP_TIMER10_MPU
  [0] WKUPDEP_UART4_MPU rw — Wakeup dependency from UART4 module (SWakeup signal) towards MPU + L3MAIN1 + L3MAIN2 domains
    values as PM_L4PER_TIMER10_WKDEP.WKUPDEP_TIMER10_MPU
0xA60 PM_L4PER_MMC5_WKDEP access per field reset 0x0 — This register controls wakeup dependency based on MMC5 service requests.
  [3] WKUPDEP_MMC5_SDMA rw — Wakeup dependency from MMCSD5 module (SWakeup signal) towards SDMA + L3MAIN2 domains
    values as PM_L4PER_TIMER10_WKDEP.WKUPDEP_TIMER10_MPU
  [0] WKUPDEP_MMC5_MPU rw — Wakeup dependency from MMCSD5 module (SWakeup signal) towards MPU + L3MAIN1 + L3MAIN2 domains
    values as PM_L4PER_TIMER10_WKDEP.WKUPDEP_TIMER10_MPU
0xA64 RM_L4PER_MMC5_CONTEXT reset 0x101 — This register contains dedicated MMC5 context statuses. [warm reset insensitive]
  fields as RM_L4PER_MMC3_CONTEXT
0xA68 PM_L4PER_I2C5_WKDEP access per field reset 0x0 — This register controls wakeup dependency based on I2C5 service requests.
  [0] WKUPDEP_I2C5_IRQ_MPU rw — Wakeup dependency from I2C5 module (SWakeup_irq signal) towards MPU + L3MAIN1 + L3MAIN2 domains
    values as PM_L4PER_TIMER10_WKDEP.WKUPDEP_TIMER10_MPU
0xA6C RM_L4PER_I2C5_CONTEXT — This register contains dedicated I2C5 context statuses. [warm reset insensitive]
  fields as RM_L4CFG_SAR_ROM_CONTEXT
0xA70 PM_L4PER_UART5_WKDEP access per field reset 0x0 — This register controls wakeup dependency based on UART5 service requests.
  [3] WKUPDEP_UART5_SDMA rw — Wakeup dependency from UART5 module (SWakeup signal) towards SDMA + L3MAIN2 domains
    values as PM_L4PER_TIMER10_WKDEP.WKUPDEP_TIMER10_MPU
  [0] WKUPDEP_UART5_MPU rw — Wakeup dependency from UART5 module (SWakeup signal) towards MPU + L3MAIN1 + L3MAIN2 domains
    values as PM_L4PER_TIMER10_WKDEP.WKUPDEP_TIMER10_MPU
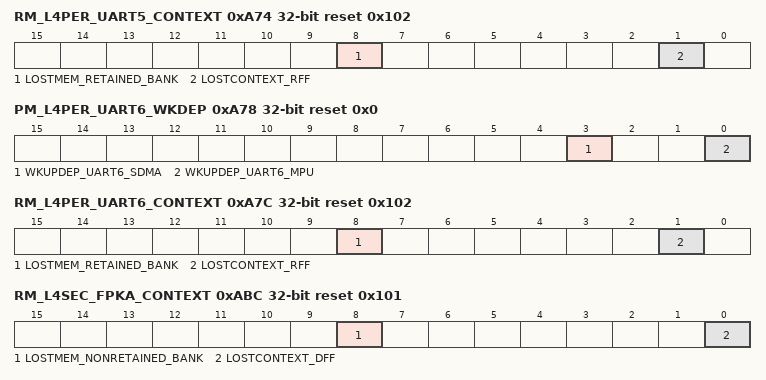
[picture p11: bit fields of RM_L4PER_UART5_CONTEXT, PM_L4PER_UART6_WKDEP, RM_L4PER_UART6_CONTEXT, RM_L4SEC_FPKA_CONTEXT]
0xA74 RM_L4PER_UART5_CONTEXT reset 0x102 — This register contains dedicated UART5 context statuses. [warm reset insensitive]
  fields as RM_L4PER_UART1_CONTEXT
0xA78 PM_L4PER_UART6_WKDEP access per field reset 0x0 — This register controls wakeup dependency based on UART6 service requests.
  [3] WKUPDEP_UART6_SDMA rw — Wakeup dependency from UART6 module (SWakeup signal) towards SDMA + L3MAIN2 domains
    values as PM_L4PER_TIMER10_WKDEP.WKUPDEP_TIMER10_MPU
  [0] WKUPDEP_UART6_MPU rw — Wakeup dependency from UART6 module (SWakeup signal) towards MPU + L3MAIN1 + L3MAIN2 domains
    values as PM_L4PER_TIMER10_WKDEP.WKUPDEP_TIMER10_MPU
0xA7C RM_L4PER_UART6_CONTEXT reset 0x102 — This register contains dedicated UART6 context statuses. [warm reset insensitive]
  fields as RM_L4PER_UART1_CONTEXT
0xAA4 RM_L4SEC_AES1_CONTEXT reset 0x2 — This register contains dedicated AES1 context statuses. [warm reset insensitive]
  fields as RM_L3MAIN2_GPMC_CONTEXT
0xAAC RM_L4SEC_AES2_CONTEXT reset 0x2 — This register contains dedicated AES2 context statuses. [warm reset insensitive]
  fields as RM_L3MAIN2_GPMC_CONTEXT
0xAB4 RM_L4SEC_DES3DES_CONTEXT reset 0x2 — This register contains dedicated DES3DES context statuses. [warm reset insensitive]
  fields as RM_L3MAIN2_GPMC_CONTEXT
0xABC RM_L4SEC_FPKA_CONTEXT reset 0x101 — This register contains dedicated FPKA context statuses. [warm reset insensitive]
  fields as RM_L4PER_MMC3_CONTEXT
0xAC4 RM_L4SEC_RNG_CONTEXT reset 0x2 — This register contains dedicated RNG context statuses. [warm reset insensitive]
  fields as RM_L3MAIN2_GPMC_CONTEXT
0xACC RM_L4SEC_SHA2MD5_CONTEXT reset 0x2 — This register contains dedicated SHA2MD5 context statuses. [warm reset insensitive]
  fields as RM_L3MAIN2_GPMC_CONTEXT
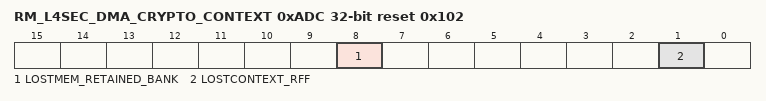
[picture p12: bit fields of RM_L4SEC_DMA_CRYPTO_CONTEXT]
0xADC RM_L4SEC_DMA_CRYPTO_CONTEXT reset 0x102 — This register contains dedicated DMA_CRYPTO context statuses. [warm reset insensitive]
  fields as RM_L4PER_UART1_CONTEXT
